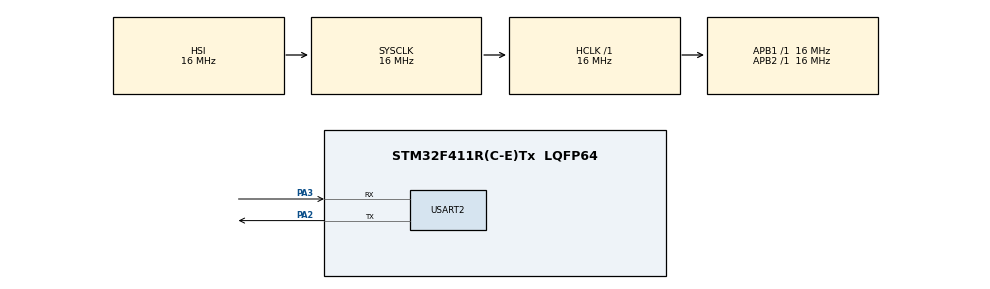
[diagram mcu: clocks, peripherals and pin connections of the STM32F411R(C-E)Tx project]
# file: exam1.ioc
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Mcu.Family=STM32F4
Mcu.Name=STM32F411R(C-E)Tx
Mcu.Package=LQFP64
NVIC.PriorityGroup=NVIC_PRIORITYGROUP_4
PA13.Mode=Serial_Wire
PA13.Signal=SYS_JTMS-SWDIO
PA14.Mode=Serial_Wire
PA14.Signal=SYS_JTCK-SWCLK
PA2.Mode=Asynchronous
PA2.Signal=USART2_TX
PA3.Mode=Asynchronous
PA3.Signal=USART2_RX
PC14-OSC32_IN.Mode=LSE-External-Oscillator
PC14-OSC32_IN.Signal=RCC_OSC32_IN
PC15-OSC32_OUT.Mode=LSE-External-Oscillator
PC15-OSC32_OUT.Signal=RCC_OSC32_OUT
ProjectManager.HeapSize=0x200
ProjectManager.StackSize=0x400
ProjectManager.TargetToolchain=STM32CubeIDE
RCC.AHBFreq_Value=16000000
RCC.APB1Freq_Value=16000000
RCC.APB2Freq_Value=16000000
RCC.CortexFreq_Value=16000000
RCC.HSE_VALUE=25000000
RCC.HSI_VALUE=16000000
RCC.SYSCLKFreq_VALUE=16000000
RCC.VCOOutputFreq_Value=192000000
USART2.VirtualMode=VM_ASYNC
board=custom

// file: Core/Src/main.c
/* USER CODE BEGIN Header */
/**
  ******************************************************************************
  * @file           : main.c
  * @brief          : Main program body
  ******************************************************************************
  * @attention
  *
  * Copyright (c) 2024 STMicroelectronics.
  * All rights reserved.
  *
  * This software is licensed under terms that can be found in the LICENSE file
  * in the root directory of this software component.
  * If no LICENSE file comes with this software, it is provided AS-IS.
  *
  ******************************************************************************
  */
/* USER CODE END Header */
#include "main.h"
/* USER CODE BEGIN Includes */
#include <string.h>
#include <stdio.h>
#include <math.h>
/* USER CODE END Includes */

/* USER CODE BEGIN PM */
#define STX 0x02
#define ETX 0x03
/* USER CODE END PM */

UART_HandleTypeDef huart2;

void SystemClock_Config(void);
static void MX_GPIO_Init(void);
static void MX_USART2_UART_Init(void);

/* USER CODE BEGIN 0 */
void putSerial(int inValue){
	// 지난 시간에 파이썬에서 쓸 통신 프로토콜을 동일하게 사용할 것
	char txBuffer[5] = { 0, };
	txBuffer[0] = STX;

	txBuffer[1] = (inValue & 0x7f) | 0x80;
	txBuffer[2] = ((inValue >> 7) & 0x7f) | 0x80;
	// 00{01 1010 0}[110 1100]이라는 data를 보낼려함
		// 110 1100 | 0b1000 0000 = 0b1110 1100
		// 011 0100 | 0b1000 0000 = 0b1011 0100

	// over flow가 나면 알아서 버려지므로 걱정하지말고 편하게 짜면됨
	txBuffer[3] = txBuffer[0] + txBuffer[1] + txBuffer[2];
	txBuffer[4] = ETX;

	HAL_UART_Transmit(&huart2, txBuffer, 5, 1);
}

void putSerial2(int inValue){
	char txBuffer[4] = { 0, };
	txBuffer[0] = 0x11;
	txBuffer[1] = 0x22;
	// 16 bit 데이터를 8bit로 쪼개기 위한 방법
	// 정석
		// txBuffer[2] = inValue;
		// txBuffer[3] = inValue >> 8;
		// 설명
			// inValue = 0b 1010 1010 0011 1100;
			// txBuffer[2] = 0b 1010 1010 0011 1100;
			//													(리틀엔디안이라 뒤에 8자리만 담김)
			// txBuffer[3] = 0b 1010 1010 0011 1100 >> 8;
			//						 = 0b 1010 1010;
	memcpy(&txBuffer[2], &inValue, 2);

	HAL_UART_Transmit(&huart2, txBuffer, 4, 1);
}
/* USER CODE END 0 */

int main(void)
{

  /* MCU Configuration--------------------------------------------------------*/

  /* Reset of all peripherals, Initializes the Flash interface and the Systick. */
  HAL_Init();

  /* Configure the system clock */
  SystemClock_Config();

  /* Initialize all configured peripherals */
  MX_GPIO_Init();
  MX_USART2_UART_Init();
  /* USER CODE BEGIN 2 */
  char str[] = {"App start!\n"};
  HAL_UART_Transmit(&huart2, str, strlen(str), 10);
  /* USER CODE END 2 */

  /* Infinite loop */
  /* USER CODE BEGIN WHILE */
  while (1)
  {
	  static int angle = 0;
	  angle++;
	  angle %= 360;

	  // change to radian
	  float value = sin(angle * 3.14 / 180) * 8192 + 8192;
	  		// * 16384는 2^14임
	  				// 2^10 = 1024, 2^12 = 4096, 2^14 = 16384, 2^15 = 32768, 2^16 = 65536
	  		// 음수 값을 없애기 위해서, 8192를 곱하고 최대 값이 16384가 되도록 8192를 더람
	  putSerial2((int)value);
	  HAL_Delay(1);
    /* USER CODE END WHILE */

  }
}

void SystemClock_Config(void)
{
  RCC_OscInitTypeDef RCC_OscInitStruct = {0};
  RCC_ClkInitTypeDef RCC_ClkInitStruct = {0};

  /** Configure the main internal regulator output voltage
  */
  __HAL_RCC_PWR_CLK_ENABLE();
  __HAL_PWR_VOLTAGESCALING_CONFIG(PWR_REGULATOR_VOLTAGE_SCALE1);

  /** Initializes the RCC Oscillators according to the specified parameters
  * in the RCC_OscInitTypeDef structure.
  */
  RCC_OscInitStruct.OscillatorType = RCC_OSCILLATORTYPE_HSI;
  RCC_OscInitStruct.HSIState = RCC_HSI_ON;
  RCC_OscInitStruct.HSICalibrationValue = RCC_HSICALIBRATION_DEFAULT;
  RCC_OscInitStruct.PLL.PLLState = RCC_PLL_NONE;
  if (HAL_RCC_OscConfig(&RCC_OscInitStruct) != HAL_OK)
  {
    Error_Handler();
  }

  /** Initializes the CPU, AHB and APB buses clocks
  */
  RCC_ClkInitStruct.ClockType = RCC_CLOCKTYPE_HCLK|RCC_CLOCKTYPE_SYSCLK
                              |RCC_CLOCKTYPE_PCLK1|RCC_CLOCKTYPE_PCLK2;
  RCC_ClkInitStruct.SYSCLKSource = RCC_SYSCLKSOURCE_HSI;
  RCC_ClkInitStruct.AHBCLKDivider = RCC_SYSCLK_DIV1;
  RCC_ClkInitStruct.APB1CLKDivider = RCC_HCLK_DIV1;
  RCC_ClkInitStruct.APB2CLKDivider = RCC_HCLK_DIV1;

  if (HAL_RCC_ClockConfig(&RCC_ClkInitStruct, FLASH_LATENCY_0) != HAL_OK)
  {
    Error_Handler();
  }
}

static void MX_USART2_UART_Init(void)
{

  huart2.Instance = USART2;
  huart2.Init.BaudRate = 115200;
  huart2.Init.WordLength = UART_WORDLENGTH_8B;
  huart2.Init.StopBits = UART_STOPBITS_1;
  huart2.Init.Parity = UART_PARITY_NONE;
  huart2.Init.Mode = UART_MODE_TX_RX;
  huart2.Init.HwFlowCtl = UART_HWCONTROL_NONE;
  huart2.Init.OverSampling = UART_OVERSAMPLING_16;
  if (HAL_UART_Init(&huart2) != HAL_OK)
  {
    Error_Handler();
  }

}

static void MX_GPIO_Init(void)
{

  /* GPIO Ports Clock Enable */
  __HAL_RCC_GPIOC_CLK_ENABLE();
  __HAL_RCC_GPIOA_CLK_ENABLE();

}

void Error_Handler(void)
{
  __disable_irq();
  while (1)
  {
  }
}
